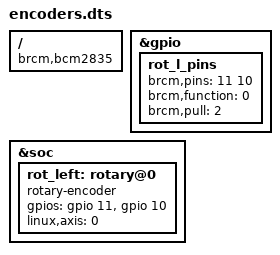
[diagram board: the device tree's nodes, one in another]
/*

Device tree overlay for KURT's 2 rotary encoders.

Sources:
http://www.mjoldfield.com/atelier/2017/03/rpi-devicetree.html
https://github.com/kenrestivo/linux/blob/b74f2674fd49a1d58baf5dbe5f0fbe052b65f873/arch/arm/boot/dts/overlays/rotaries-overlay.dts

*/

/dts-v1/;
/plugin/;

/ {
    /*
    First-gen Pis (A, B, B+, Zero, Compute): BCM2835 chip, BCM2708 family
    Pi 2: BCM2836 chip, BCM2709 family
    Pi 3: BCM2837 chip, BCM2709 family
    This overlay *should* work with all of them. I don't know if specifying
    just the chip or family is enough, so just LIST ALL OF THEM.
    */
    compatible = "brcm,bcm2835", "brcm,bcm2708",
                 "brcm,bcm2836", "brcm,bcm2709",
                 "brcm,bcm2837";
    // FIXME: bcm2708 should be enough

    fragment@0 {
        target = <&gpio>;
        __overlay__ {
            rot_l_pins: rot_l_pins {
                brcm,pins = <11 10>; // <A B>
                brcm,function = <0>;
                brcm,pull = <2>;    // 0: none, 1: pull-down, 2: pull-up
            };
        };
    };

    fragment@1 {
        target = <&soc>;
        __overlay__ {
            rot_left: rotary@0 {
                compatible = "rotary-encoder";
                gpios = <&gpio 11 0>, <&gpio 10 0>;
                linux,axis = <0>;   // REL_X / ABS_X
                //rotary-encoder,relative-axis;
            };
        };
    };

    /*
    __overrides__ {
        rot_l_a = <&rot_l_pins>,"bytes.0";
        rot_l_b = <&rot_l_pins>,"bytes.1";
        // TODO: ...
    };
    */
};
